AUTOSAR XML (schema 00048)
package /ComponentTypes
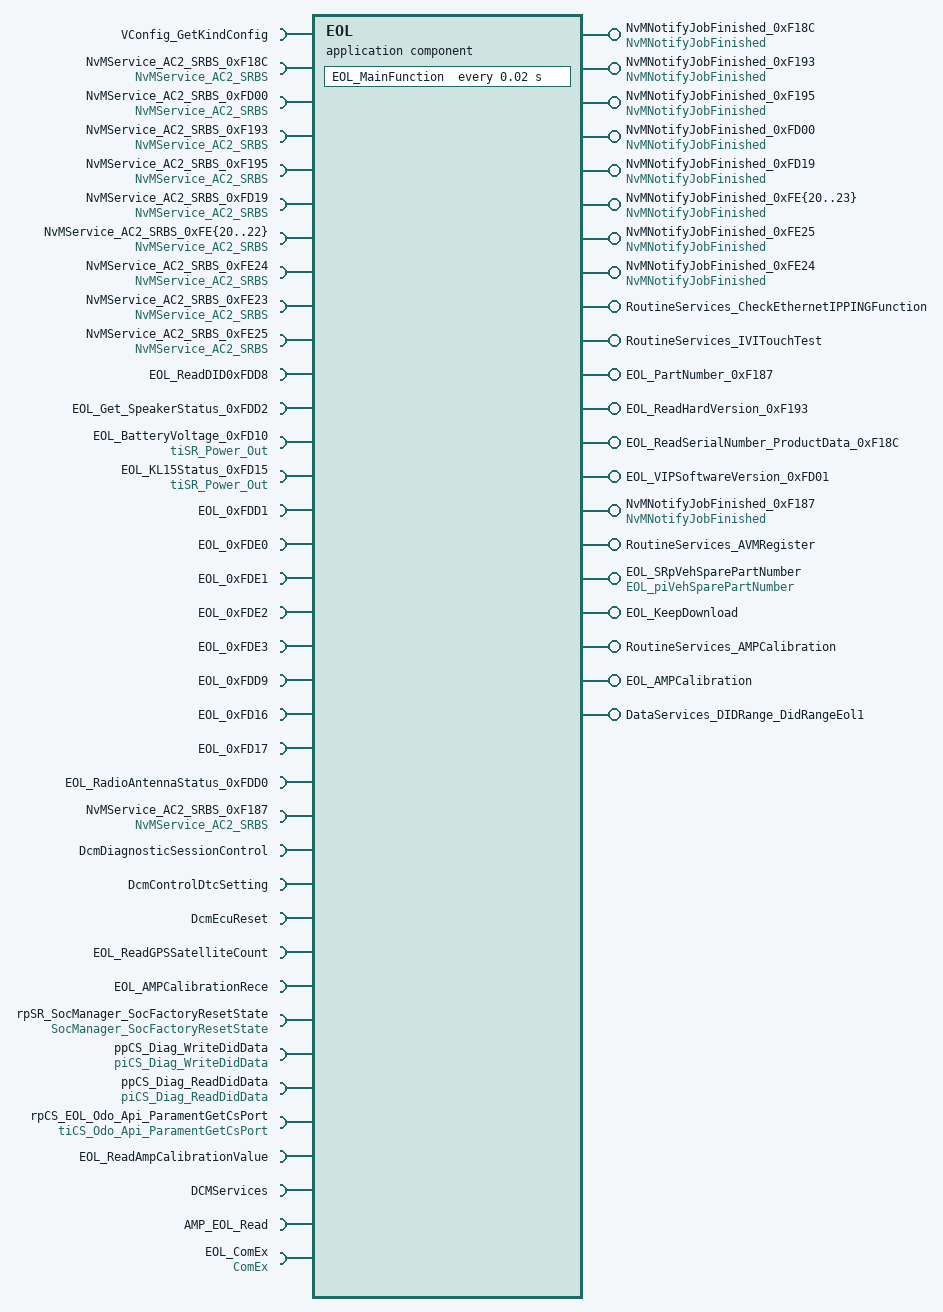
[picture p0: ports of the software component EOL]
  application sw component type EOL
    require port VConfig_GetKindConfig: client-com-spec=Operation_VConfig_GetKindConfig, required-interface=VConfig_GetKindConfig
    require port NvMService_AC2_SRBS_0xF18C: required-com-specs=[WriteBlock, SetRamBlockStatus, ReadBlock, GetErrorStatus], required-interface=NvMService_AC2_SRBS
    provide port NvMNotifyJobFinished_0xF18C: server-com-spec{operation=JobFinished, queue-length=1}, provided-interface=NvMNotifyJobFinished
    require port NvMService_AC2_SRBS_0xFD00: required-com-specs=[WriteBlock, SetRamBlockStatus, ReadBlock, GetErrorStatus], required-interface=NvMService_AC2_SRBS
    require port NvMService_AC2_SRBS_0xF193: required-com-specs=[WriteBlock, SetRamBlockStatus, ReadBlock, GetErrorStatus], required-interface=NvMService_AC2_SRBS
    require port NvMService_AC2_SRBS_0xF195: required-com-specs=[WriteBlock, SetRamBlockStatus, ReadBlock, GetErrorStatus], required-interface=NvMService_AC2_SRBS
    provide port NvMNotifyJobFinished_0xF193: server-com-spec{operation=JobFinished, queue-length=1}, provided-interface=NvMNotifyJobFinished
    provide port NvMNotifyJobFinished_0xF195: server-com-spec{operation=JobFinished, queue-length=1}, provided-interface=NvMNotifyJobFinished
    provide port NvMNotifyJobFinished_0xFD00: server-com-spec{operation=JobFinished, queue-length=1}, provided-interface=NvMNotifyJobFinished
    require port NvMService_AC2_SRBS_0xFD19: required-com-specs=[WriteBlock, SetRamBlockStatus, ReadBlock, GetErrorStatus], required-interface=NvMService_AC2_SRBS
    provide port NvMNotifyJobFinished_0xFD19: server-com-spec{operation=JobFinished, queue-length=1}, provided-interface=NvMNotifyJobFinished
    6 x require port, all with required-com-specs=[WriteBlock, SetRamBlockStatus, ReadBlock, GetErrorStatus], required-interface=NvMService_AC2_SRBS:
      NvMService_AC2_SRBS_0xFE{20..22}
      NvMService_AC2_SRBS_0xFE24
      NvMService_AC2_SRBS_0xFE23
      NvMService_AC2_SRBS_0xFE25
    8 x provide port:
      NvMNotifyJobFinished_0xFE{20..23}: server-com-spec{operation=JobFinished, queue-length=1}, provided-interface=NvMNotifyJobFinished
      NvMNotifyJobFinished_0xFE25: server-com-spec{operation=JobFinished, queue-length=1}, provided-interface=NvMNotifyJobFinished
      NvMNotifyJobFinished_0xFE24: server-com-spec{operation=JobFinished, queue-length=1}, provided-interface=NvMNotifyJobFinished
      RoutineServices_CheckEthernetIPPINGFunction: provided-com-specs=[{operation=RequestResults, queue-length=1}, {operation=Start, queue-length=1}], provided-interface=RoutineServices_CheckEthernetIPPINGFunction
      RoutineServices_IVITouchTest: provided-com-specs=[{operation=RequestResults, queue-length=1}, {operation=Start, queue-length=1}], provided-interface=RoutineServices_IVITouchTest
    12 x require port:
      EOL_ReadDID0xFDD8: client-com-spec=EOL_GetReadHardInputForCluster, required-interface=EOL_ReadDID0xFDD8
      EOL_Get_SpeakerStatus_0xFDD2: client-com-spec=EOL_Get_SpeakerStatus_0xFDD2, required-interface=EOL_Get_SpeakerStatus_0xFDD2
      EOL_BatteryVoltage_0xFD10: nonqueued-receiver-com-spec{data-element=SystemStateOut, filter=data-filter-type=ALWAYS}, required-interface=tiSR_Power_Out
      EOL_KL15Status_0xFD15: nonqueued-receiver-com-spec{data-element=SystemStateOut, filter=data-filter-type=ALWAYS}, required-interface=tiSR_Power_Out
      EOL_0xFDD1: client-com-spec=EOL_ReadMICStatus, required-interface=EOL_0xFDD1
      EOL_0xFDE0: required-interface=EOL_0xFDE0
      EOL_0xFDE1: client-com-spec=EOL_ReadWatchDogCnt, required-interface=EOL_0xFDE1
      EOL_0xFDE2: client-com-spec=EOL_ReadResetInformation, required-interface=EOL_0xFDE2
      EOL_0xFDE3: required-interface=EOL_0xFDE3
      EOL_0xFDD9: client-com-spec=EOL_WriteValueForDispalyEnable, required-interface=EOL_0xFDD9
      EOL_0xFD16: client-com-spec=EOL_FactoryReset, required-interface=EOL_0xFD16
      EOL_0xFD17: client-com-spec=EOL_Get_MCUAMP_Temperature_0xFD17, required-interface=EOL_0xFD17
    5 x provide port:
      EOL_PartNumber_0xF187: nonqueued-sender-com-spec{data-element=PartNumber_0xF187, init-value=13 x 0}, provided-interface=EOL_PartNumber_0xF187
      EOL_ReadHardVersion_0xF193: nonqueued-sender-com-spec{data-element=ReadHardVersion_0xF193, init-value=15 x 0}, provided-interface=EOL_ReadHardVersion_0xF193
      EOL_ReadSerialNumber_ProductData_0xF18C: nonqueued-sender-com-spec{data-element=ReadSerialNumber_ProductData_0xF18C, init-value=20 x 0}, provided-interface=EOL_ReadSerialNumber_ProductData_0xF18C
      EOL_VIPSoftwareVersion_0xFD01: nonqueued-sender-com-spec{data-element=VIPSoftwareVersion_0xFD01, init-value=[0, 0, 0, 0]}, provided-interface=EOL_VIPSoftwareVersion_0xFD01
      NvMNotifyJobFinished_0xF187: server-com-spec{operation=JobFinished, queue-length=1}, provided-interface=NvMNotifyJobFinished
    require port EOL_RadioAntennaStatus_0xFDD0: nonqueued-receiver-com-spec{data-element=RadioAntennaStatus_0xFDD0, filter=data-filter-type=ALWAYS, init-value=[0, 0, 0]}, required-interface=EOL_RadioAntennaStatus_0xFDD0
    require port NvMService_AC2_SRBS_0xF187: required-com-specs=[GetErrorStatus, ReadBlock, SetRamBlockStatus, WriteBlock], required-interface=NvMService_AC2_SRBS
    provide port RoutineServices_AVMRegister: provided-com-specs=[{operation=RequestResults, queue-length=1}, {operation=Start, queue-length=1}], provided-interface=RoutineServices_AVMRegister
    provide port EOL_SRpVehSparePartNumber: nonqueued-sender-com-spec{data-element=SparePartNumber, init-value=13 x 0}, provided-interface=EOL_piVehSparePartNumber
    provide port EOL_KeepDownload: nonqueued-sender-com-spec=keepDownloadRID, provided-interface=EOL_KeepDownload
    4 x require port:
      DcmDiagnosticSessionControl: mode-switch-receiver-com-spec=DcmDiagnosticSessionControl, required-interface=DcmDiagnosticSessionControl
      DcmControlDtcSetting: mode-switch-receiver-com-spec=DcmControlDtcSetting, required-interface=DcmControlDtcSetting
      DcmEcuReset: mode-switch-receiver-com-spec=DcmEcuReset, required-interface=DcmEcuReset
      EOL_ReadGPSSatelliteCount: nonqueued-receiver-com-spec{data-element=GPSSatelliteCount, filter=data-filter-type=ALWAYS, init-value=0}, required-interface=EOL_ReadGPSSatelliteCount
    provide port RoutineServices_AMPCalibration: provided-com-specs=[{operation=RequestResults, queue-length=1}, {operation=Start, queue-length=1}], provided-interface=RoutineServices_AMPCalibration
    provide port EOL_AMPCalibration: nonqueued-sender-com-spec{data-element=AMPCalibration, init-value=0}, provided-interface=EOL_AMPCalibration
    9 x require port:
      EOL_AMPCalibrationRece: nonqueued-receiver-com-spec{data-element=EOLReceive, filter=data-filter-type=ALWAYS, init-value=10 x 0}, required-interface=EOL_AMPCalibrationRece
      rpSR_SocManager_SocFactoryResetState: nonqueued-receiver-com-spec{data-element=SocFactoryResetReady, filter=data-filter-type=ALWAYS, init-value=0}, required-interface=SocManager_SocFactoryResetState
      ppCS_Diag_WriteDidData: client-com-spec=Operation, required-interface=piCS_Diag_WriteDidData
      ppCS_Diag_ReadDidData: client-com-spec=Operation, required-interface=piCS_Diag_ReadDidData
      rpCS_EOL_Odo_Api_ParamentGetCsPort: client-com-spec=Operation, required-interface=tiCS_Odo_Api_ParamentGetCsPort
      EOL_ReadAmpCalibrationValue: nonqueued-receiver-com-spec{data-element=AmpCalibrationValue, filter=data-filter-type=ALWAYS, init-value=[17, 0, 0, 0, 0, 0, 0, 0, 0]}, required-interface=EOL_ReadAmpCalibrationValue
      DCMServices: required-interface=DCMServices
        required-com-specs:
          GetRequestKind
          SetActiveDiagnostic
          GetSecurityLevel
          ResetToDefaultSession
          GetSesCtrlType
          GetActiveProtocol
      AMP_EOL_Read: client-com-spec=Operation, required-interface=AMP_EOL_Read
      EOL_ComEx: required-com-specs=[GetRxE2EStatus, ReceiveSignal, SendSignal], required-interface=ComEx
    provide port DataServices_DIDRange_DidRangeEol1: provided-interface=DataServices_DIDRange_DidRangeEol1
      provided-com-specs:
        operation=IsDidAvailable, queue-length=1
        operation=WriteDidData, queue-length=1
        operation=ReadDidData, queue-length=1
    behavior EOL_InternalBehavior
      ar-typed-per-instance-memorys:
        12 x data, all with sw-calibration-access=READ-ONLY:
          NvBlockNeed_0xF18C_MirrorBlock: type=A_20Bytes
          NvBlockNeed_0xF193_MirrorBlock: type=EOL_15Bytes
          NvBlockNeed_0xF195_MirrorBlock: type=A_17Bytes
          NvBlockNeed_0xFD00_MirrorBlock: type=RW_0xFD00
          NvBlockNeed_0xFD19_MirrorBlock: type=A_1Bytes
          NvBlockNeed_0xFE{20..22}_MirrorBlock: type=A_1Bytes
          NvBlockNeed_0xFE23_MirrorBlock: type=EOL_2Bytes
          NvBlockNeed_0xFE24_MirrorBlock: type=A_1Bytes
          NvBlockNeed_0xFE25_MirrorBlock: type=EOL_2Bytes
          NvBlockNeed_0xF187_MirrorBlock: type=EOL_13Bytes
      init event EOL_InitEvent: start-on-event=EOL_Init
      timing event TMT_EOL_MainFunction: start-on-event=EOL_MainFunction, period=0.02
      23 x operation invoked event:
        OIT_NvMNotifyJobFinished_0xF18C_JobFinished_NvMNotifyJobFinished_0xF18C_JobFinished: start-on-event=NvMNotifyJobFinished_0xF18C_JobFinished, operation=NvMNotifyJobFinished_0xF18C.JobFinished
        OIT_NvMNotifyJobFinished_0xF193_JobFinished_NvMNotifyJobFinished_0xF193_JobFinished: start-on-event=NvMNotifyJobFinished_0xF193_JobFinished, operation=NvMNotifyJobFinished_0xF193.JobFinished
        OIT_NvMNotifyJobFinished_0xF195_JobFinished_NvMNotifyJobFinished_0xF195_JobFinished: start-on-event=NvMNotifyJobFinished_0xF195_JobFinished, operation=NvMNotifyJobFinished_0xF195.JobFinished
        OIT_NvMNotifyJobFinished_0xFD00_JobFinished_NvMNotifyJobFinished_0xFD00_JobFinished: start-on-event=NvMNotifyJobFinished_0xFD00_JobFinished, operation=NvMNotifyJobFinished_0xFD00.JobFinished
        OIT_NvMNotifyJobFinished_0xFD19_JobFinished_NvMNotifyJobFinished_0xFD19_JobFinished: start-on-event=NvMNotifyJobFinished_0xFD19_JobFinished, operation=NvMNotifyJobFinished_0xFD19.JobFinished
        OIT_NvMNotifyJobFinished_0xFE20_JobFinished_NvMNotifyJobFinished_0xFE20_JobFinished: start-on-event=NvMNotifyJobFinished_0xFE20_JobFinished, operation=NvMNotifyJobFinished_0xFE20.JobFinished
        OIT_NvMNotifyJobFinished_0xFE21_JobFinished_NvMNotifyJobFinished_0xFE21_JobFinished: start-on-event=NvMNotifyJobFinished_0xFE21_JobFinished, operation=NvMNotifyJobFinished_0xFE21.JobFinished
        OIT_NvMNotifyJobFinished_0xFE24_JobFinished_NvMNotifyJobFinished_0xFE24_JobFinished: start-on-event=NvMNotifyJobFinished_0xFE24_JobFinished, operation=NvMNotifyJobFinished_0xFE24.JobFinished
        OIT_NvMNotifyJobFinished_0xFE23_JobFinished_NvMNotifyJobFinished_0xFE23_JobFinished: start-on-event=NvMNotifyJobFinished_0xFE23_JobFinished, operation=NvMNotifyJobFinished_0xFE23.JobFinished
        OIT_NvMNotifyJobFinished_0xFE25_JobFinished_NvMNotifyJobFinished_0xFE25_JobFinished: start-on-event=NvMNotifyJobFinished_0xFE25_JobFinished, operation=NvMNotifyJobFinished_0xFE25.JobFinished
        OIT_NvMNotifyJobFinished_0xFE22_JobFinished_NvMNotifyJobFinished_0xFE22_JobFinished: start-on-event=NvMNotifyJobFinished_0xFE22_JobFinished, operation=NvMNotifyJobFinished_0xFE22.JobFinished
        OIT_RoutineServices_CheckEthernetIPPINGFunction_RequestResults_RoutineServices_CheckEthernetIPPINGFunction_RequestResults: start-on-event=RoutineServices_CheckEthernetIPPINGFunction_RequestResults, operation=RoutineServices_CheckEthernetIPPINGFunction.RequestResults
        OIT_RoutineServices_CheckEthernetIPPINGFunction_Start_RoutineServices_CheckEthernetIPPINGFunction_Start: start-on-event=RoutineServices_CheckEthernetIPPINGFunction_Start, operation=RoutineServices_CheckEthernetIPPINGFunction.Start
        OIT_RoutineServices_IVITouchTest_RequestResults_RoutineServices_IVITouchTest_RequestResults: start-on-event=RoutineServices_IVITouchTest_RequestResults, operation=RoutineServices_IVITouchTest.RequestResults
        OIT_RoutineServices_IVITouchTest_Start_RoutineServices_IVITouchTest_Start: start-on-event=RoutineServices_IVITouchTest_Start, operation=RoutineServices_IVITouchTest.Start
        OIT_NvMNotifyJobFinished_0xF187_JobFinished_NvMNotifyJobFinished_0xF187_JobFinished: start-on-event=NvMNotifyJobFinished_0xF187_JobFinished, operation=NvMNotifyJobFinished_0xF187.JobFinished
        OIT_RoutineServices_AVMRegister_RequestResults_RoutineServices_AVMRegister_RequestResults: start-on-event=RoutineServices_AVMRegister_RequestResults, operation=RoutineServices_AVMRegister.RequestResults
        OIT_RoutineServices_AVMRegister_Start_RoutineServices_AVMRegister_Start: start-on-event=RoutineServices_AVMRegister_Start, operation=RoutineServices_AVMRegister.Start
        OIT_RoutineServices_AMPCalibration_RequestResults_RoutineServices_AMPCalibration_RequestResults: start-on-event=RoutineServices_AMPCalibration_RequestResults, operation=RoutineServices_AMPCalibration.RequestResults
        OIT_RoutineServices_AMPCalibration_Start_RoutineServices_AMPCalibration_Start: start-on-event=RoutineServices_AMPCalibration_Start, operation=RoutineServices_AMPCalibration.Start
        OIT_DataServices_DIDRange_DidRangeEol1_IsDidAvailable_DataServices_DIDRange_DidRangeEol1_IsDidAvailable: start-on-event=DataServices_DIDRange_DidRangeEol1_IsDidAvailable, operation=DataServices_DIDRange_DidRangeEol1.IsDidAvailable
        OIT_DataServices_DIDRange_DidRangeEol1_WriteDidData_DataServices_DIDRange_DidRangeEol1_WriteDidData: start-on-event=DataServices_DIDRange_DidRangeEol1_WriteDidData, operation=DataServices_DIDRange_DidRangeEol1.WriteDidData
        OIT_DataServices_DIDRange_DidRangeEol1_ReadDidData_DataServices_DIDRange_DidRangeEol1_ReadDidData: start-on-event=DataServices_DIDRange_DidRangeEol1_ReadDidData, operation=DataServices_DIDRange_DidRangeEol1.ReadDidData
      25 x runnable:
        EOL_Init
          data-receive-point-by-arguments:
            7 x access:
              REC_EOL_AMPCalibrationRece_EOLReceive: accessed-variable=EOL_AMPCalibrationRece.EOLReceive
              REC_EOL_BatteryVoltage_0xFD10_SystemStateOut: accessed-variable=EOL_BatteryVoltage_0xFD10.SystemStateOut
              REC_EOL_KL15Status_0xFD15_SystemStateOut: accessed-variable=EOL_KL15Status_0xFD15.SystemStateOut
              REC_EOL_RadioAntennaStatus_0xFDD0_RadioAntennaStatus_0xFDD0: accessed-variable=EOL_RadioAntennaStatus_0xFDD0.RadioAntennaStatus_0xFDD0
              REC_EOL_ReadAmpCalibrationValue_AmpCalibrationValue: accessed-variable=EOL_ReadAmpCalibrationValue.AmpCalibrationValue
              REC_EOL_ReadGPSSatelliteCount_GPSSatelliteCount: accessed-variable=EOL_ReadGPSSatelliteCount.GPSSatelliteCount
              REC_rpSR_SocManager_SocFactoryResetState_SocFactoryResetReady: accessed-variable=rpSR_SocManager_SocFactoryResetState.SocFactoryResetReady
          data-send-points:
            7 x access:
              SEND_EOL_AMPCalibration_AMPCalibration: accessed-variable=EOL_AMPCalibration.AMPCalibration
              SEND_EOL_KeepDownload_keepDownloadRID: accessed-variable=EOL_KeepDownload.keepDownloadRID
              SEND_EOL_PartNumber_0xF187_PartNumber_0xF187: accessed-variable=EOL_PartNumber_0xF187.PartNumber_0xF187
              SEND_EOL_ReadHardVersion_0xF193_ReadHardVersion_0xF193: accessed-variable=EOL_ReadHardVersion_0xF193.ReadHardVersion_0xF193
              SEND_EOL_ReadSerialNumber_ProductData_0xF18C_ReadSerialNumber_ProductData_0xF18C: accessed-variable=EOL_ReadSerialNumber_ProductData_0xF18C.ReadSerialNumber_ProductData_0xF18C
              SEND_EOL_SRpVehSparePartNumber_SparePartNumber: accessed-variable=EOL_SRpVehSparePartNumber.SparePartNumber
              SEND_EOL_VIPSoftwareVersion_0xFD01_VIPSoftwareVersion_0xFD01: accessed-variable=EOL_VIPSoftwareVersion_0xFD01.VIPSoftwareVersion_0xFD01
        EOL_MainFunction
          data-receive-point-by-arguments:
            access REC_rpSR_Power_SocFactoryResetState_SocFactoryResetReady: accessed-variable=rpSR_SocManager_SocFactoryResetState.SocFactoryResetReady
          data-send-points:
            access SEND_EOL_piVehSparePartNumber_SparePartNumber: accessed-variable=EOL_SRpVehSparePartNumber.SparePartNumber
            access SEND_EOL_KeepDownload_keepDownloadRID: accessed-variable=EOL_KeepDownload.keepDownloadRID
          mode-access-points:
            DcmControlDtcSetting.DcmControlDtcSetting
            DcmDiagnosticSessionControl.DcmDiagnosticSessionControl
            DcmEcuReset.DcmEcuReset
          69 x sync call:
            SC_NvMService_AC2_SRBS_0xF18C_GetErrorStatus: operation=NvMService_AC2_SRBS_0xF18C.GetErrorStatus
            SC_NvMService_AC2_SRBS_0xF18C_ReadBlock: operation=NvMService_AC2_SRBS_0xF18C.ReadBlock
            SC_NvMService_AC2_SRBS_0xF18C_SetRamBlockStatus: operation=NvMService_AC2_SRBS_0xF18C.SetRamBlockStatus
            SC_NvMService_AC2_SRBS_0xF18C_WriteBlock: operation=NvMService_AC2_SRBS_0xF18C.WriteBlock
            SC_NvMService_AC2_SRBS_0xF193_GetErrorStatus: operation=NvMService_AC2_SRBS_0xF193.GetErrorStatus
            SC_NvMService_AC2_SRBS_0xF193_ReadBlock: operation=NvMService_AC2_SRBS_0xF193.ReadBlock
            SC_NvMService_AC2_SRBS_0xF193_SetRamBlockStatus: operation=NvMService_AC2_SRBS_0xF193.SetRamBlockStatus
            SC_NvMService_AC2_SRBS_0xF193_WriteBlock: operation=NvMService_AC2_SRBS_0xF193.WriteBlock
            SC_NvMService_AC2_SRBS_0xF195_GetErrorStatus: operation=NvMService_AC2_SRBS_0xF195.GetErrorStatus
            SC_NvMService_AC2_SRBS_0xF195_ReadBlock: operation=NvMService_AC2_SRBS_0xF195.ReadBlock
            SC_NvMService_AC2_SRBS_0xF195_SetRamBlockStatus: operation=NvMService_AC2_SRBS_0xF195.SetRamBlockStatus
            SC_NvMService_AC2_SRBS_0xF195_WriteBlock: operation=NvMService_AC2_SRBS_0xF195.WriteBlock
            SC_NvMService_AC2_SRBS_0xFD00_GetErrorStatus: operation=NvMService_AC2_SRBS_0xFD00.GetErrorStatus
            SC_NvMService_AC2_SRBS_0xFD00_ReadBlock: operation=NvMService_AC2_SRBS_0xFD00.ReadBlock
            SC_NvMService_AC2_SRBS_0xFD00_SetRamBlockStatus: operation=NvMService_AC2_SRBS_0xFD00.SetRamBlockStatus
            SC_NvMService_AC2_SRBS_0xFD00_WriteBlock: operation=NvMService_AC2_SRBS_0xFD00.WriteBlock
            SC_NvMService_AC2_SRBS_0xFD19_GetErrorStatus: operation=NvMService_AC2_SRBS_0xFD19.GetErrorStatus
            SC_NvMService_AC2_SRBS_0xFD19_ReadBlock: operation=NvMService_AC2_SRBS_0xFD19.ReadBlock
            SC_NvMService_AC2_SRBS_0xFD19_SetRamBlockStatus: operation=NvMService_AC2_SRBS_0xFD19.SetRamBlockStatus
            SC_NvMService_AC2_SRBS_0xFD19_WriteBlock: operation=NvMService_AC2_SRBS_0xFD19.WriteBlock
            SC_NvMService_AC2_SRBS_0xFE20_GetErrorStatus: operation=NvMService_AC2_SRBS_0xFE20.GetErrorStatus
            SC_NvMService_AC2_SRBS_0xFE20_ReadBlock: operation=NvMService_AC2_SRBS_0xFE20.ReadBlock
            SC_NvMService_AC2_SRBS_0xFE20_SetRamBlockStatus: operation=NvMService_AC2_SRBS_0xFE20.SetRamBlockStatus
            SC_NvMService_AC2_SRBS_0xFE20_WriteBlock: operation=NvMService_AC2_SRBS_0xFE20.WriteBlock
            SC_NvMService_AC2_SRBS_0xFE21_GetErrorStatus: operation=NvMService_AC2_SRBS_0xFE21.GetErrorStatus
            SC_NvMService_AC2_SRBS_0xFE21_ReadBlock: operation=NvMService_AC2_SRBS_0xFE21.ReadBlock
            SC_NvMService_AC2_SRBS_0xFE21_SetRamBlockStatus: operation=NvMService_AC2_SRBS_0xFE21.SetRamBlockStatus
            SC_NvMService_AC2_SRBS_0xFE21_WriteBlock: operation=NvMService_AC2_SRBS_0xFE21.WriteBlock
            SC_NvMService_AC2_SRBS_0xFE22_GetErrorStatus: operation=NvMService_AC2_SRBS_0xFE22.GetErrorStatus
            SC_NvMService_AC2_SRBS_0xFE22_ReadBlock: operation=NvMService_AC2_SRBS_0xFE22.ReadBlock
            SC_NvMService_AC2_SRBS_0xFE22_SetRamBlockStatus: operation=NvMService_AC2_SRBS_0xFE22.SetRamBlockStatus
            SC_NvMService_AC2_SRBS_0xFE22_WriteBlock: operation=NvMService_AC2_SRBS_0xFE22.WriteBlock
            SC_NvMService_AC2_SRBS_0xFE23_GetErrorStatus: operation=NvMService_AC2_SRBS_0xFE23.GetErrorStatus
            SC_NvMService_AC2_SRBS_0xFE23_ReadBlock: operation=NvMService_AC2_SRBS_0xFE23.ReadBlock
            SC_NvMService_AC2_SRBS_0xFE23_SetRamBlockStatus: operation=NvMService_AC2_SRBS_0xFE23.SetRamBlockStatus
            SC_NvMService_AC2_SRBS_0xFE23_WriteBlock: operation=NvMService_AC2_SRBS_0xFE23.WriteBlock
            SC_NvMService_AC2_SRBS_0xFE24_GetErrorStatus: operation=NvMService_AC2_SRBS_0xFE24.GetErrorStatus
            SC_NvMService_AC2_SRBS_0xFE24_ReadBlock: operation=NvMService_AC2_SRBS_0xFE24.ReadBlock
            SC_NvMService_AC2_SRBS_0xFE24_SetRamBlockStatus: operation=NvMService_AC2_SRBS_0xFE24.SetRamBlockStatus
            SC_NvMService_AC2_SRBS_0xFE24_WriteBlock: operation=NvMService_AC2_SRBS_0xFE24.WriteBlock
            SC_NvMService_AC2_SRBS_0xFE25_GetErrorStatus: operation=NvMService_AC2_SRBS_0xFE25.GetErrorStatus
            SC_NvMService_AC2_SRBS_0xFE25_ReadBlock: operation=NvMService_AC2_SRBS_0xFE25.ReadBlock
            SC_NvMService_AC2_SRBS_0xFE25_SetRamBlockStatus: operation=NvMService_AC2_SRBS_0xFE25.SetRamBlockStatus
            SC_NvMService_AC2_SRBS_0xFE25_WriteBlock: operation=NvMService_AC2_SRBS_0xFE25.WriteBlock
            SC_NvMService_AC2_SRBS_0xF187_GetErrorStatus: operation=NvMService_AC2_SRBS_0xF187.GetErrorStatus
            SC_NvMService_AC2_SRBS_0xF187_ReadBlock: operation=NvMService_AC2_SRBS_0xF187.ReadBlock
            SC_NvMService_AC2_SRBS_0xF187_SetRamBlockStatus: operation=NvMService_AC2_SRBS_0xF187.SetRamBlockStatus
            SC_NvMService_AC2_SRBS_0xF187_WriteBlock: operation=NvMService_AC2_SRBS_0xF187.WriteBlock
            SC_piCS_Diag_ReadDidData_Operation: operation=ppCS_Diag_ReadDidData.Operation
            SC_piCS_Diag_WriteDidData_Operation: operation=ppCS_Diag_WriteDidData.Operation
            SC_DCMServices_GetSecurityLevel: operation=DCMServices.GetSecurityLevel
            SC_AMP_EOL_Read_Operation: operation=AMP_EOL_Read.Operation
            SC_EOL_ComEx_GetRxE2EStatus: operation=EOL_ComEx.GetRxE2EStatus
            SC_EOL_ComEx_ReceiveSignal: operation=EOL_ComEx.ReceiveSignal
            SC_EOL_ComEx_SendSignal: operation=EOL_ComEx.SendSignal
            SC_DCMServices_GetActiveProtocol: operation=DCMServices.GetActiveProtocol
            SC_DCMServices_GetRequestKind: operation=DCMServices.GetRequestKind
            SC_DCMServices_GetSesCtrlType: operation=DCMServices.GetSesCtrlType
            SC_DCMServices_ResetToDefaultSession: operation=DCMServices.ResetToDefaultSession
            SC_DCMServices_SetActiveDiagnostic: operation=DCMServices.SetActiveDiagnostic
            SC_EOL_0xFD16_EOL_FactoryReset: operation=EOL_0xFD16.EOL_FactoryReset
            SC_EOL_0xFD17_EOL_Get_MCUAMP_Temperature_0xFD17: operation=EOL_0xFD17.EOL_Get_MCUAMP_Temperature_0xFD17
            SC_EOL_0xFDD1_EOL_ReadMICStatus: operation=EOL_0xFDD1.EOL_ReadMICStatus
            SC_EOL_0xFDD9_EOL_WriteValueForDispalyEnable: operation=EOL_0xFDD9.EOL_WriteValueForDispalyEnable
            SC_EOL_0xFDE1_EOL_ReadWatchDogCnt: operation=EOL_0xFDE1.EOL_ReadWatchDogCnt
            SC_EOL_0xFDE2_EOL_ReadResetInformation: operation=EOL_0xFDE2.EOL_ReadResetInformation
            SC_EOL_Get_SpeakerStatus_0xFDD2_EOL_Get_SpeakerStatus_0xFDD2: operation=EOL_Get_SpeakerStatus_0xFDD2.EOL_Get_SpeakerStatus_0xFDD2
            SC_VConfig_GetKindConfig_Operation_VConfig_GetKindConfig: operation=VConfig_GetKindConfig.Operation_VConfig_GetKindConfig
            SC_rpCS_EOL_Odo_Api_ParamentGetCsPort_Operation: operation=rpCS_EOL_Odo_Api_ParamentGetCsPort.Operation
        NvMNotifyJobFinished_0xF18C_JobFinished
        NvMNotifyJobFinished_0xF193_JobFinished
        NvMNotifyJobFinished_0xF195_JobFinished
        NvMNotifyJobFinished_0xFD00_JobFinished
        NvMNotifyJobFinished_0xFD19_JobFinished
        NvMNotifyJobFinished_0xFE20_JobFinished
        NvMNotifyJobFinished_0xFE21_JobFinished
        NvMNotifyJobFinished_0xFE24_JobFinished
        NvMNotifyJobFinished_0xFE23_JobFinished
        NvMNotifyJobFinished_0xFE25_JobFinished
        NvMNotifyJobFinished_0xFE22_JobFinished
        RoutineServices_CheckEthernetIPPINGFunction_RequestResults
        RoutineServices_CheckEthernetIPPINGFunction_Start
        RoutineServices_IVITouchTest_RequestResults
        RoutineServices_IVITouchTest_Start
        NvMNotifyJobFinished_0xF187_JobFinished
        RoutineServices_AVMRegister_RequestResults
        RoutineServices_AVMRegister_Start
        RoutineServices_AMPCalibration_RequestResults
          data-receive-point-by-arguments:
            access REC_EOL_AMPCalibrationRece_EOLReceive: accessed-variable=EOL_AMPCalibrationRece.EOLReceive
            access REC_EOL_ReadAmpCalibrationValue_AmpCalibrationValue: accessed-variable=EOL_ReadAmpCalibrationValue.AmpCalibrationValue
          data-send-points:
            access SEND_EOL_AMPCalibration_AMPCalibration: accessed-variable=EOL_AMPCalibration.AMPCalibration
        RoutineServices_AMPCalibration_Start
          data-send-points:
            access SEND_EOL_AMPCalibration_AMPCalibration: accessed-variable=EOL_AMPCalibration.AMPCalibration
        DataServices_DIDRange_DidRangeEol1_IsDidAvailable
        DataServices_DIDRange_DidRangeEol1_WriteDidData
        DataServices_DIDRange_DidRangeEol1_ReadDidData
          data-receive-point-by-arguments:
            access REC_EOL_BatteryVoltage_0xFD10_SystemStateOut: accessed-variable=EOL_BatteryVoltage_0xFD10.SystemStateOut
          sync call SC_EOL_ReadDID0xFDD8_EOL_GetReadHardInputForCluster: operation=EOL_ReadDID0xFDD8.EOL_GetReadHardInputForCluster
      12 x swc service dependency:
        NvBlockNeed_0xF18C
          assigned-datas:
            role=ramBlock, used-data-element=NvBlockNeed_0xF18C_MirrorBlock
            role=defaultValue, used-parameter-element=NvBlockNeed_0xF18C_DefaultValue
            role=defaultValue, used-parameter-element=NvBlockNeed_0xF18C_DefaultValue
            role=defaultValue, used-parameter-element=NvBlockNeed_0xF18C_DefaultValue
          assigned-ports:
            port-prototype=NvMNotifyJobFinished_0xF18C, role=NvMNotifyJobFinished
            port-prototype=NvMService_AC2_SRBS_0xF18C, role=NvMService_AC2_SRBS
          service-needs:
            nv block needs NvBlockNeed_0xF18C: n-data-sets=0, ram-block-status-control=API, reliability=NO-PROTECTION, restore-at-start=true, store-at-shutdown=true
        NvBlockNeed_0xF193
          assigned-datas:
            role=ramBlock, used-data-element=NvBlockNeed_0xF193_MirrorBlock
            role=defaultValue, used-parameter-element=NvBlockNeed_0xF193_DefaultValue
            role=defaultValue, used-parameter-element=NvBlockNeed_0xF193_DefaultValue
            role=defaultValue, used-parameter-element=NvBlockNeed_0xF193_DefaultValue
          assigned-ports:
            port-prototype=NvMNotifyJobFinished_0xF193, role=NvMNotifyJobFinished
            port-prototype=NvMService_AC2_SRBS_0xF193, role=NvMService_AC2_SRBS
          service-needs:
            nv block needs NvBlockNeed_0xF193: n-data-sets=0, ram-block-status-control=API, reliability=NO-PROTECTION, restore-at-start=true, store-at-shutdown=true
        NvBlockNeed_0xF195
          assigned-datas:
            role=ramBlock, used-data-element=NvBlockNeed_0xF195_MirrorBlock
            role=defaultValue, used-parameter-element=NvBlockNeed_0xF195_DefaultValue
            role=defaultValue, used-parameter-element=NvBlockNeed_0xF195_DefaultValue
            role=defaultValue, used-parameter-element=NvBlockNeed_0xF195_DefaultValue
          assigned-ports:
            port-prototype=NvMService_AC2_SRBS_0xF195, role=NvMService_AC2_SRBS
            port-prototype=NvMNotifyJobFinished_0xF195, role=NvMNotifyJobFinished
          service-needs:
            nv block needs NvBlockNeed_0xF195: n-data-sets=0, ram-block-status-control=API, reliability=NO-PROTECTION, restore-at-start=true, store-at-shutdown=true
        NvBlockNeed_0xFD00
          assigned-datas:
            role=ramBlock, used-data-element=NvBlockNeed_0xFD00_MirrorBlock
            role=defaultValue, used-parameter-element=NvBlockNeed_0xFD00_DefaultValue
            role=defaultValue, used-parameter-element=NvBlockNeed_0xFD00_DefaultValue
            role=defaultValue, used-parameter-element=NvBlockNeed_0xFD00_DefaultValue
          assigned-ports:
            port-prototype=NvMService_AC2_SRBS_0xFD00, role=NvMService_AC2_SRBS
            port-prototype=NvMNotifyJobFinished_0xFD00, role=NvMNotifyJobFinished
          service-needs:
            nv block needs NvBlockNeed_0xFD00: n-data-sets=0, ram-block-status-control=API, reliability=NO-PROTECTION, restore-at-start=true, store-at-shutdown=true
        NvBlockNeed_0xFD19
          assigned-datas:
            role=ramBlock, used-data-element=NvBlockNeed_0xFD19_MirrorBlock
            role=defaultValue, used-parameter-element=NvBlockNeed_0xFD19_DefaultValue
            role=defaultValue, used-parameter-element=NvBlockNeed_0xFD19_DefaultValue
            role=defaultValue, used-parameter-element=NvBlockNeed_0xFD19_DefaultValue
          assigned-ports:
            port-prototype=NvMNotifyJobFinished_0xFD19, role=NvMNotifyJobFinished
            port-prototype=NvMService_AC2_SRBS_0xFD19, role=NvMService_AC2_SRBS
          service-needs:
            nv block needs NvBlockNeed_0xFD19: n-data-sets=0, ram-block-status-control=API, reliability=NO-PROTECTION, restore-at-start=true, store-at-shutdown=true
        NvBlockNeed_0xFE20
          assigned-datas:
            role=ramBlock, used-data-element=NvBlockNeed_0xFE20_MirrorBlock
            role=defaultValue, used-parameter-element=NvBlockNeed_0xFE20_DefaultValue
            role=defaultValue, used-parameter-element=NvBlockNeed_0xFE20_DefaultValue
            role=defaultValue, used-parameter-element=NvBlockNeed_0xFE20_DefaultValue
          assigned-ports:
            port-prototype=NvMNotifyJobFinished_0xFE20, role=NvMNotifyJobFinished
            port-prototype=NvMService_AC2_SRBS_0xFE20, role=NvMService_AC2_SRBS
          service-needs:
            nv block needs NvBlockNeed_0xFE20: n-data-sets=0, ram-block-status-control=API, reliability=NO-PROTECTION, restore-at-start=true, store-at-shutdown=true
        NvBlockNeed_0xFE21
          assigned-datas:
            role=ramBlock, used-data-element=NvBlockNeed_0xFE21_MirrorBlock
            role=defaultValue, used-parameter-element=NvBlockNeed_0xFE21_DefaultValue
            role=defaultValue, used-parameter-element=NvBlockNeed_0xFE21_DefaultValue
            role=defaultValue, used-parameter-element=NvBlockNeed_0xFE21_DefaultValue
          assigned-ports:
            port-prototype=NvMNotifyJobFinished_0xFE21, role=NvMNotifyJobFinished
            port-prototype=NvMService_AC2_SRBS_0xFE21, role=NvMService_AC2_SRBS
          service-needs:
            nv block needs NvBlockNeed_0xFE21: n-data-sets=0, ram-block-status-control=API, reliability=NO-PROTECTION, restore-at-start=true, store-at-shutdown=true
        NvBlockNeed_0xFE22
          assigned-datas:
            role=ramBlock, used-data-element=NvBlockNeed_0xFE22_MirrorBlock
            role=defaultValue, used-parameter-element=NvBlockNeed_0xFE22_DefaultValue
            role=defaultValue, used-parameter-element=NvBlockNeed_0xFE22_DefaultValue
            role=defaultValue, used-parameter-element=NvBlockNeed_0xFE22_DefaultValue
          assigned-ports:
            port-prototype=NvMService_AC2_SRBS_0xFE22, role=NvMService_AC2_SRBS
            port-prototype=NvMNotifyJobFinished_0xFE22, role=NvMNotifyJobFinished
          service-needs:
            nv block needs NvBlockNeed_0xFE22: n-data-sets=0, ram-block-status-control=API, reliability=NO-PROTECTION, restore-at-start=true, store-at-shutdown=true
        NvBlockNeed_0xFE23
          assigned-datas:
            role=ramBlock, used-data-element=NvBlockNeed_0xFE23_MirrorBlock
            role=defaultValue, used-parameter-element=NvBlockNeed_0xFE23_DefaultValue
            role=defaultValue, used-parameter-element=NvBlockNeed_0xFE23_DefaultValue
            role=defaultValue, used-parameter-element=NvBlockNeed_0xFE23_DefaultValue
          assigned-ports:
            port-prototype=NvMService_AC2_SRBS_0xFE23, role=NvMService_AC2_SRBS
            port-prototype=NvMNotifyJobFinished_0xFE23, role=NvMNotifyJobFinished
          service-needs:
            nv block needs NvBlockNeed_0xFE23: n-data-sets=0, ram-block-status-control=API, reliability=NO-PROTECTION, restore-at-start=true, store-at-shutdown=true
        NvBlockNeed_0xFE24
          assigned-datas:
            role=ramBlock, used-data-element=NvBlockNeed_0xFE24_MirrorBlock
            role=defaultValue, used-parameter-element=NvBlockNeed_0xFE24_DefaultValue
            role=defaultValue, used-parameter-element=NvBlockNeed_0xFE24_DefaultValue
            role=defaultValue, used-parameter-element=NvBlockNeed_0xFE24_DefaultValue
          assigned-ports:
            port-prototype=NvMNotifyJobFinished_0xFE24, role=NvMNotifyJobFinished
            port-prototype=NvMService_AC2_SRBS_0xFE24, role=NvMService_AC2_SRBS
          service-needs:
            nv block needs NvBlockNeed_0xFE24: n-data-sets=0, ram-block-status-control=API, reliability=NO-PROTECTION, restore-at-start=true, store-at-shutdown=true
        NvBlockNeed_0xFE25
          assigned-datas:
            role=ramBlock, used-data-element=NvBlockNeed_0xFE25_MirrorBlock
            role=defaultValue, used-parameter-element=NvBlockNeed_0xFE25_DefaultValue
            role=defaultValue, used-parameter-element=NvBlockNeed_0xFE25_DefaultValue
            role=defaultValue, used-parameter-element=NvBlockNeed_0xFE25_DefaultValue
          assigned-ports:
            port-prototype=NvMNotifyJobFinished_0xFE25, role=NvMNotifyJobFinished
            port-prototype=NvMService_AC2_SRBS_0xFE25, role=NvMService_AC2_SRBS
          service-needs:
            nv block needs NvBlockNeed_0xFE25: n-data-sets=0, ram-block-status-control=API, reliability=NO-PROTECTION, restore-at-start=true, store-at-shutdown=true
        NvBlockNeed_0xF187
          assigned-datas:
            role=ramBlock, used-data-element=NvBlockNeed_0xF187_MirrorBlock
            role=defaultValue, used-parameter-element=NvBlockNeed_0xF187_DefaultValue
            role=defaultValue, used-parameter-element=NvBlockNeed_0xF187_DefaultValue
          assigned-ports:
            port-prototype=NvMNotifyJobFinished_0xF187, role=NvMNotifyJobFinished
            port-prototype=NvMService_AC2_SRBS_0xF187, role=NvMService_AC2_SRBS
          service-needs:
            nv block needs NvBlockNeed_0xF187: n-data-sets=0, ram-block-status-control=API, reliability=NO-PROTECTION, restore-at-start=true, store-at-shutdown=true
      shared-parameters:
        16 x parameter data prototype, all with sw-calibration-access=READ-WRITE:
          NvBlockNeed_0xF18C_DefaultValue: type=A_20Bytes, init-value=20 x 70
          NvBlockNeed_0xF193_DefaultValue: type=EOL_15Bytes, init-value=15 x 70
          NvBlockNeed_0xF195_DefaultValue: type=A_17Bytes
          NvBlockNeed_0xFD00_DefaultValue: type=RW_0xFD00
          NvBlockNeed_0xFD19_DefaultValue: type=A_1Bytes
          NvBlockNeed_0xFE{20..22}_DefaultValue: type=A_1Bytes
          NvBlockNeed_0xFE23_DefaultValue: type=EOL_2Bytes
          NvBlockNeed_0xFE24_DefaultValue: type=A_1Bytes
          NvBlockNeed_0xFE25_DefaultValue: type=EOL_2Bytes
          NvBlockNeed_0xFDD9_DefaultValue: type=EOL_2Bytes
          NvBlockNeed_0xF187_DefaultValue: type=EOL_13Bytes, init-value=13 x 70
          NvBlockNeed_EnterEOLSession_DefaultValue: type=EOL4Bytes
          NvBlockNeed_UIN_DefaultValue: type=A_20Bytes
          NvBlockNeed_EOLUIN_DefaultValue: type=A_20Bytes, init-value=20 x 70
  swc implementation EOL_Implementation: behavior=EOL_InternalBehavior
    code-descriptors:
      code Default: artifact-descriptors=autosar-engineering-object=category=SWSRC
